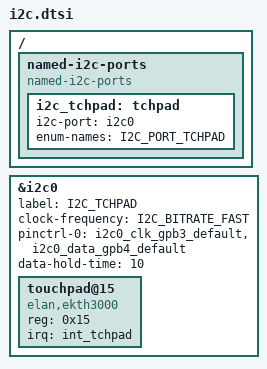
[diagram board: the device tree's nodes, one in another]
/* Copyright 2023 The ChromiumOS Authors
 * Use of this source code is governed by a BSD-style license that can be
 * found in the LICENSE file.
 */

/ {
	named-i2c-ports {
		compatible = "named-i2c-ports";

		i2c_tchpad: tchpad {
			i2c-port = <&i2c0>;
			enum-names = "I2C_PORT_TCHPAD";
		};
	};
};

&i2c0 {
	status = "okay";
	label = "I2C_TCHPAD";
	clock-frequency = <I2C_BITRATE_FAST>;
	pinctrl-0 = <&i2c0_clk_gpb3_default
		     &i2c0_data_gpb4_default>;
	pinctrl-names = "default";
	data-hold-time = <10>;

	touchpad@15 {
		compatible = "elan,ekth3000";
		status = "okay";
		reg = <0x15>;
		irq = <&int_tchpad>;
	};
};
